# HT32F52342_52 register map
File version: 1.0
CPU: CM0+ r0p1, little endian, no MPU, no FPU, 4 interrupt priority bits
Registers are 32-bit, read-write, reset 0x0 unless marked. A register's access mark holds for its fields unless they carry their own. Offsets are from the block's base; [hi:lo] are bit positions; {n}, {i} and the like mark numbered series.

## UART0
Base 0x40001000
Same registers: UART1 0x40041000
0x00 UART_URDR
  [8:0] DB
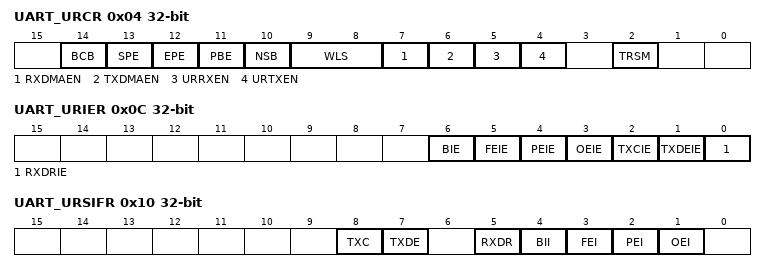
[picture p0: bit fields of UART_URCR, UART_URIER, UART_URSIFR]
0x04 UART_URCR
  [14] BCB, [13] SPE, [12] EPE, [11] PBE, [10] NSB, [9:8] WLS, [7] RXDMAEN, [6] TXDMAEN, [5] URRXEN, [4] URTXEN, [2] TRSM
0x0C UART_URIER
  [6] BIE, [5] FEIE, [4] PEIE, [3] OEIE, [2] TXCIE, [1] TXDEIE, [0] RXDRIE
0x10 UART_URSIFR
  [8] TXC, [7] TXDE, [5] RXDR, [4] BII, [3] FEI, [2] PEI, [1] OEI
0x24 UART_URDLR
  [15:0] BRD
0x28 UART_URTSTR
  [1:0] LBM

## SCI
Base 0x40043000
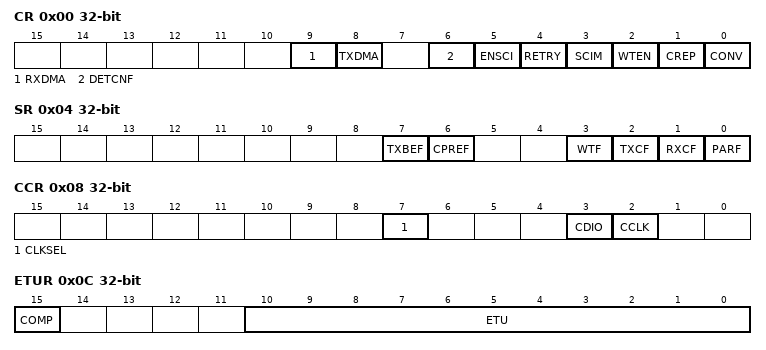
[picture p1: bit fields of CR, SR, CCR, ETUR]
0x00 CR
  [9] RXDMA, [8] TXDMA, [6] DETCNF, [5] ENSCI, [4] RETRY, [3] SCIM, [2] WTEN, [1] CREP, [0] CONV
0x04 SR
  [7] TXBEF, [6] CPREF, [3] WTF, [2] TXCF, [1] RXCF, [0] PARF
0x08 CCR
  [7] CLKSEL, [3] CDIO, [2] CCLK
0x0C ETUR
  [15] COMP, [10:0] ETU
0x10 GTR
  [8:0] GT
0x14 WTR
  [23:0] WT
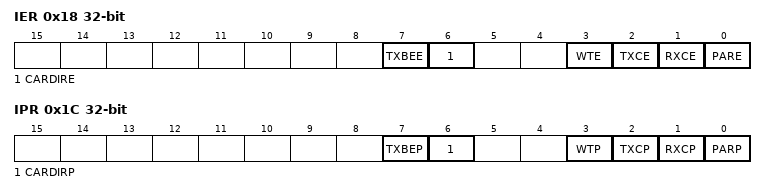
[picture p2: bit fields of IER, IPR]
0x18 IER
  [7] TXBEE, [6] CARDIRE, [3] WTE, [2] TXCE, [1] RXCE, [0] PARE
0x1C IPR
  [7] TXBEP, [6] CARDIRP, [3] WTP, [2] TXCP, [1] RXCP, [0] PARP
0x20 TXB
  [7:0] TB
0x24 RXB
  [7:0] RB
0x28 PSCR
  [5:0] PSC

## USB
Base 0x400A8000
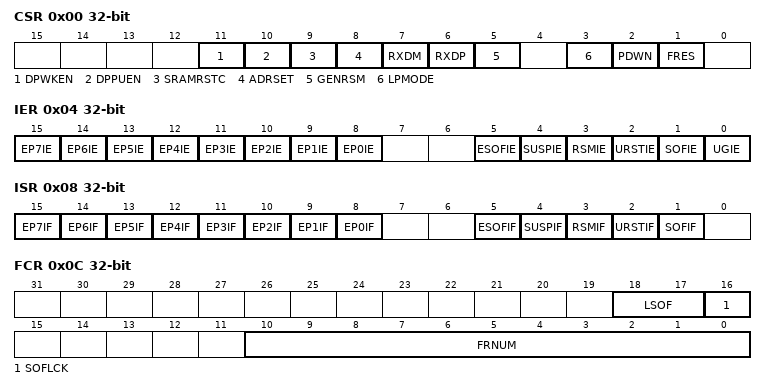
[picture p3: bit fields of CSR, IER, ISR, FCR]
0x00 CSR
  [11] DPWKEN, [10] DPPUEN, [9] SRAMRSTC, [8] ADRSET, [7] RXDM, [6] RXDP, [5] GENRSM, [3] LPMODE, [2] PDWN, [1] FRES
0x04 IER
  [n+8] EP{n}IE (n=0..7), [5] ESOFIE, [4] SUSPIE, [3] RSMIE, [2] URSTIE, [1] SOFIE, [0] UGIE
0x08 ISR
  [n+8] EP{n}IF (n=0..7), [5] ESOFIF, [4] SUSPIF, [3] RSMIF, [2] URSTIF, [1] SOFIF
0x0C FCR
  [18:17] LSOF, [16] SOFLCK, [10:0] FRNUM
0x10 DEVAR
  [6:0] DEVA
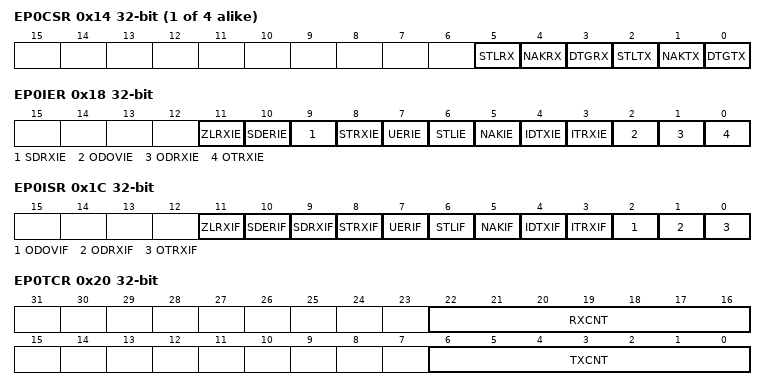
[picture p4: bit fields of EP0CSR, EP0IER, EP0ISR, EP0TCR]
{0x14+0x14*i} EP{i}CSR (i=0..3)
  [5] STLRX, [4] NAKRX, [3] DTGRX, [2] STLTX, [1] NAKTX, [0] DTGTX
0x18 EP0IER
  [11] ZLRXIE, [10] SDERIE, [9] SDRXIE, [8] STRXIE, [7] UERIE, [6] STLIE, [5] NAKIE, [4] IDTXIE, [3] ITRXIE, [2] ODOVIE, [1] ODRXIE, [0] OTRXIE
0x1C EP0ISR
  [11] ZLRXIF, [10] SDERIF, [9] SDRXIF, [8] STRXIF, [7] UERIF, [6] STLIF, [5] NAKIF, [4] IDTXIF, [3] ITRXIF, [2] ODOVIF, [1] ODRXIF, [0] OTRXIF
0x20 EP0TCR
  [22:16] RXCNT, [6:0] TXCNT
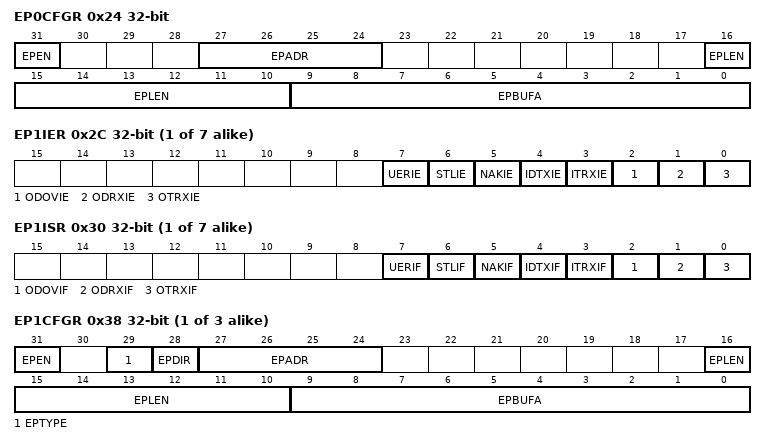
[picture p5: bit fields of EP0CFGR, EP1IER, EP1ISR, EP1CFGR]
0x24 EP0CFGR
  [31] EPEN, [27:24] EPADR, [16:10] EPLEN, [9:0] EPBUFA
{0x18+0x14*i} EP{i}IER (i=1..7)
  [7] UERIE, [6] STLIE, [5] NAKIE, [4] IDTXIE, [3] ITRXIE, [2] ODOVIE, [1] ODRXIE, [0] OTRXIE
{0x1C+0x14*i} EP{i}ISR (i=1..7)
  [7] UERIF, [6] STLIF, [5] NAKIF, [4] IDTXIF, [3] ITRXIF, [2] ODOVIF, [1] ODRXIF, [0] OTRXIF
{0x20+0x14*i} EP{i}TCR (i=1..3)
  [8:0] TCNT
{0x24+0x14*i} EP{i}CFGR (i=1..3)
  [31] EPEN, [29] EPTYPE, [28] EPDIR, [27:24] EPADR, [16:10] EPLEN, [9:0] EPBUFA
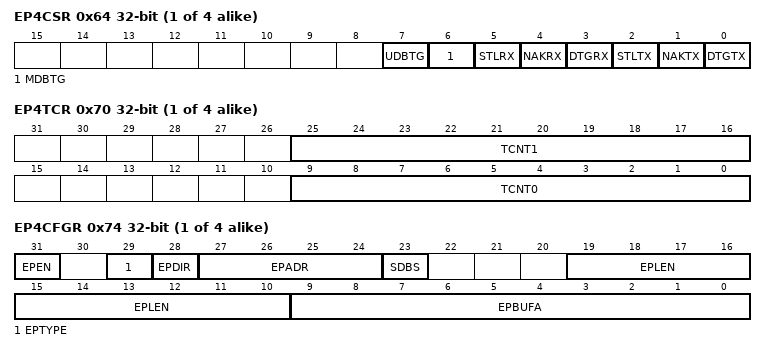
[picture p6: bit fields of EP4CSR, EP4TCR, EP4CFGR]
{0x14+0x14*i} EP{i}CSR (i=4..7)
  [7] UDBTG, [6] MDBTG, [5] STLRX, [4] NAKRX, [3] DTGRX, [2] STLTX, [1] NAKTX, [0] DTGTX
{0x20+0x14*i} EP{i}TCR (i=4..7)
  [25:16] TCNT1, [9:0] TCNT0
{0x24+0x14*i} EP{i}CFGR (i=4..7)
  [31] EPEN, [29] EPTYPE, [28] EPDIR, [27:24] EPADR, [23] SDBS, [19:10] EPLEN, [9:0] EPBUFA

## PDMA
Base 0x40090000
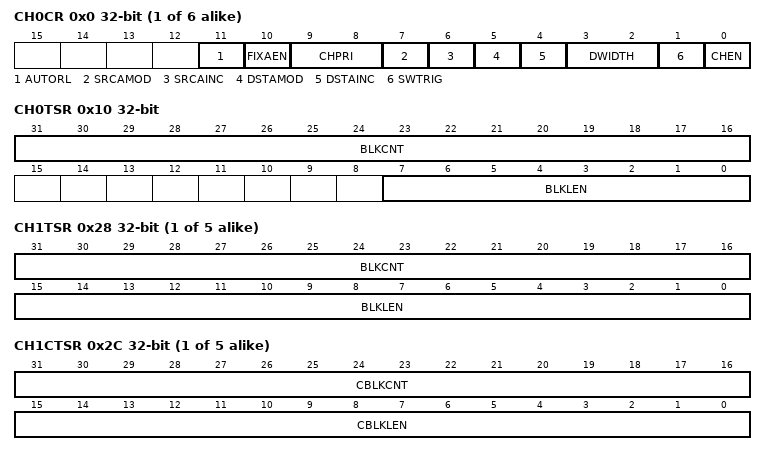
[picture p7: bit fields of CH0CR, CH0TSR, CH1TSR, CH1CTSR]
{0x0+0x18*i} CH{i}CR (i=0..5)
  [11] AUTORL, [10] FIXAEN, [9:8] CHPRI, [7] SRCAMOD, [6] SRCAINC, [5] DSTAMOD, [4] DSTAINC, [3:2] DWIDTH, [1] SWTRIG, [0] CHEN
{0x4+0x18*i} CH{i}SADR (i=0..5)
  [31:0] SADR
{0x8+0x18*i} CH{i}DADR (i=0..5)
  [31:0] DADR
0x10 CH0TSR
  [31:16] BLKCNT, [7:0] BLKLEN
0x14 CH0CTSR
  [31:16] CBLKCNT
{0x10+0x18*i} CH{i}TSR (i=1..5)
  [31:16] BLKCNT, [15:0] BLKLEN
{0x14+0x18*i} CH{i}CTSR (i=1..5)
  [31:16] CBLKCNT, [15:0] CBLKLEN
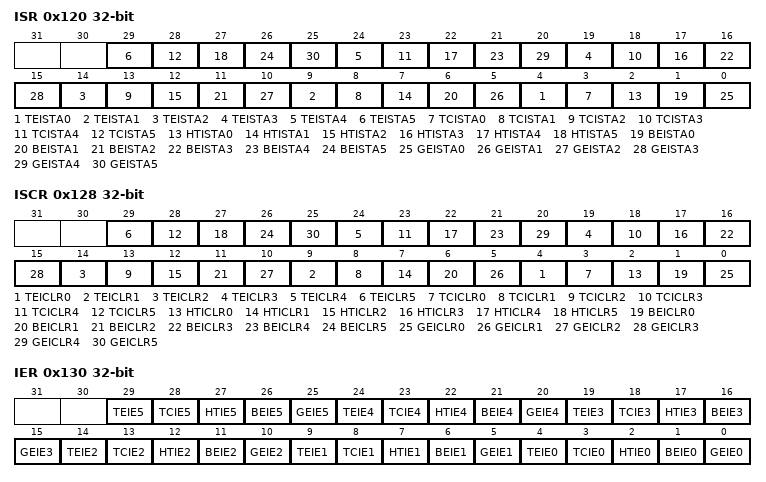
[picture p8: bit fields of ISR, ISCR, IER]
0x120 ISR
  [5n+4] TEISTA{n} (n=0..5), [5n+3] TCISTA{n} (n=0..5), [5n+2] HTISTA{n} (n=0..5), [5n+1] BEISTA{n} (n=0..5), [5n] GEISTA{n} (n=0..5)
0x128 ISCR
  [5n+4] TEICLR{n} (n=0..5), [5n+3] TCICLR{n} (n=0..5), [5n+2] HTICLR{n} (n=0..5), [5n+1] BEICLR{n} (n=0..5), [5n] GEICLR{n} (n=0..5)
0x130 IER
  [5n+4] TEIE{n} (n=0..5), [5n+3] TCIE{n} (n=0..5), [5n+2] HTIE{n} (n=0..5), [5n+1] BEIE{n} (n=0..5), [5n] GEIE{n} (n=0..5)

## EBI
Base 0x40098000
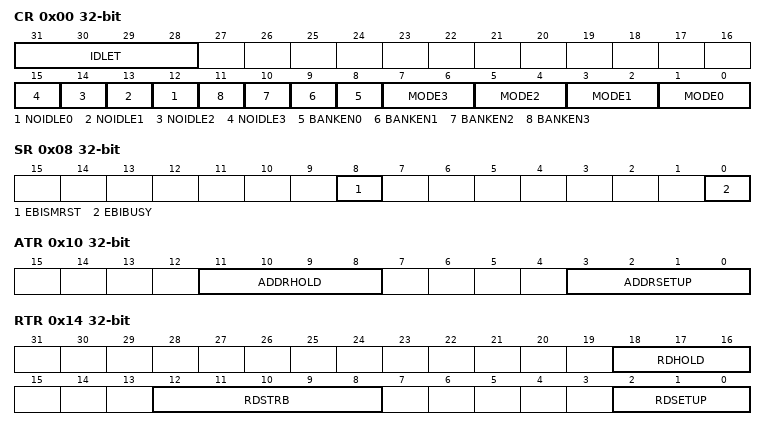
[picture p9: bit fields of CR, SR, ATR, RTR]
0x00 CR
  [31:28] IDLET, [n+12] NOIDLE{n} (n=0..3), [n+8] BANKEN{n} (n=0..3), [2n+1:2n] MODE{n} (n=0..3)
0x08 SR
  [8] EBISMRST, [0] EBIBUSY
0x10 ATR
  [11:8] ADDRHOLD, [3:0] ADDRSETUP
0x14 RTR
  [18:16] RDHOLD, [12:8] RDSTRB, [2:0] RDSETUP
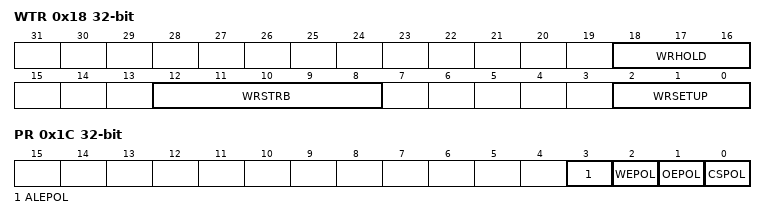
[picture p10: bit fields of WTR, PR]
0x18 WTR
  [18:16] WRHOLD, [12:8] WRSTRB, [2:0] WRSETUP
0x1C PR
  [3] ALEPOL, [2] WEPOL, [1] OEPOL, [0] CSPOL

## I2S
Base 0x40026000
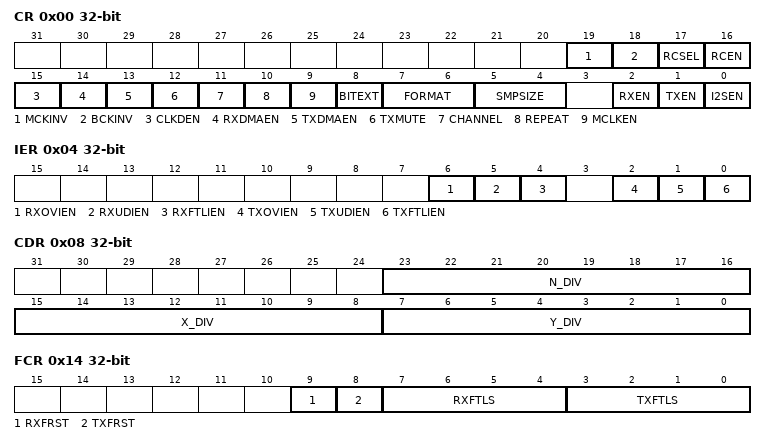
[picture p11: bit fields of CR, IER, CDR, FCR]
0x00 CR
  [19] MCKINV, [18] BCKINV, [17] RCSEL, [16] RCEN, [15] CLKDEN, [14] RXDMAEN, [13] TXDMAEN, [12] TXMUTE, [11] CHANNEL, [10] REPEAT, [9] MCLKEN, [8] BITEXT, [7:6] FORMAT, [5:4] SMPSIZE, [2] RXEN, [1] TXEN, [0] I2SEN
0x04 IER
  [6] RXOVIEN, [5] RXUDIEN, [4] RXFTLIEN, [2] TXOVIEN, [1] TXUDIEN, [0] TXFTLIEN
0x08 CDR
  [23:16] N_DIV, [15:8] X_DIV, [7:0] Y_DIV
0x0C TXDR
0x10 RXDR
0x14 FCR
  [9] RXFRST, [8] TXFRST, [7:4] RXFTLS, [3:0] TXFTLS
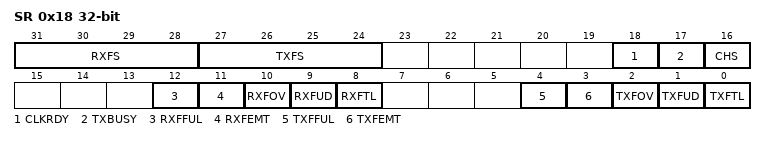
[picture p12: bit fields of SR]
0x18 SR
  [31:28] RXFS, [27:24] TXFS, [18] CLKRDY, [17] TXBUSY, [16] CHS, [12] RXFFUL, [11] RXFEMT, [10] RXFOV, [9] RXFUD, [8] RXFTL, [4] TXFFUL, [3] TXFEMT, [2] TXFOV, [1] TXFUD, [0] TXFTL
0x1C RCNTR
  [19:0] RCNTR

## CRC
Base 0x4008A000
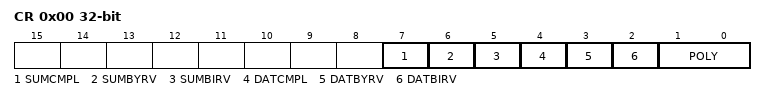
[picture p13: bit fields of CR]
0x00 CR
  [7] SUMCMPL, [6] SUMBYRV, [5] SUMBIRV, [4] DATCMPL, [3] DATBYRV, [2] DATBIRV, [1:0] POLY
0x04 SDR
  [31:0] SEED
0x08 CSR
  [31:0] CHKSUM
0x0C DR
  [31:0] DATA
